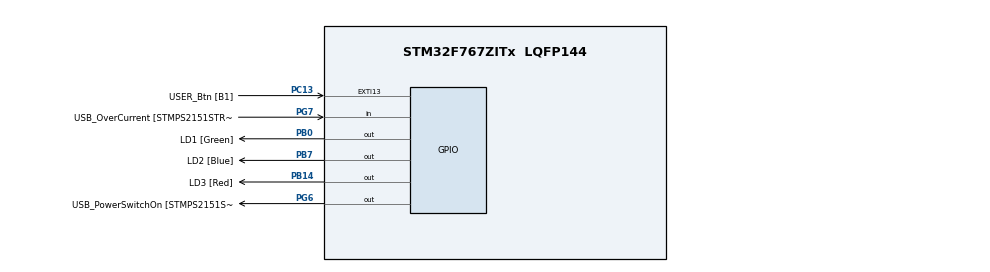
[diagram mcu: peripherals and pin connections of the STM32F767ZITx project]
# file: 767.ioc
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CORTEX_M7.CPU_DCache=Enabled
CORTEX_M7.CPU_ICache=Enabled
CORTEX_M7.FlashInterface=TCM_Enabled
Mcu.Family=STM32F7
Mcu.Name=STM32F767ZITx
Mcu.Package=LQFP144
NVIC.PriorityGroup=NVIC_PRIORITYGROUP_4
PA1.GPIO_Label=RMII_REF_CLK [LAN8742A-CZ-TR_REFCLK0]
PA1.Signal=ETH_REF_CLK
PA10.GPIO_Label=USB_ID
PA10.Signal=USB_OTG_FS_ID
PA11.GPIO_Label=USB_DM
PA11.Signal=USB_OTG_FS_DM
PA12.GPIO_Label=USB_DP
PA12.Signal=USB_OTG_FS_DP
PA13.GPIO_Label=TMS
PA13.Mode=Serial_Wire
PA13.Signal=SYS_JTMS-SWDIO
PA14.GPIO_Label=TCK
PA14.Mode=Serial_Wire
PA14.Signal=SYS_JTCK-SWCLK
PA2.GPIO_Label=RMII_MDIO [LAN8742A-CZ-TR_MDIO]
PA2.Signal=ETH_MDIO
PA7.GPIO_Label=RMII_CRS_DV [LAN8742A-CZ-TR_CRS_DV]
PA7.Signal=ETH_CRS_DV
PA8.GPIO_Label=USB_SOF [TP1]
PA8.Signal=USB_OTG_FS_SOF
PA9.GPIO_Label=USB_VBUS
PA9.Signal=USB_OTG_FS_VBUS
PB0.GPIO_Label=LD1 [Green]
PB0.Signal=GPIO_Output
PB13.GPIO_Label=RMII_TXD1 [LAN8742A-CZ-TR_TXD1]
PB13.Signal=ETH_TXD1
PB14.GPIO_Label=LD3 [Red]
PB14.Signal=GPIO_Output
PB3.GPIO_Label=SW0
PB3.Signal=SYS_JTDO-SWO
PB7.GPIO_Label=LD2 [Blue]
PB7.Signal=GPIO_Output
PC1.GPIO_Label=RMII_MDC [LAN8742A-CZ-TR_MDC]
PC1.Signal=ETH_MDC
PC13.GPIO_Label=USER_Btn [B1]
PC13.Signal=GPXTI13
PC14/OSC32_IN.Signal=RCC_OSC32_IN
PC15/OSC32_OUT.Signal=RCC_OSC32_OUT
PC4.GPIO_Label=RMII_RXD0 [LAN8742A-CZ-TR_RXD0]
PC4.Signal=ETH_RXD0
PC5.GPIO_Label=RMII_RXD1 [LAN8742A-CZ-TR_RXD1]
PC5.Signal=ETH_RXD1
PD8.GPIO_Label=STLK_RX [STM32F103CBT6_PA3]
PD8.Signal=USART3_TX
PD9.GPIO_Label=STLK_TX [STM32F103CBT6_PA2]
PD9.Signal=USART3_RX
PG11.GPIO_Label=RMII_TX_EN [LAN8742A-CZ-TR_TXEN]
PG11.Signal=ETH_TX_EN
PG13.GPIO_Label=RMII_TXD0 [LAN8742A-CZ-TR_TXD0]
PG13.Signal=ETH_TXD0
PG6.GPIO_Label=USB_PowerSwitchOn [STMPS2151STR_EN]
PG6.Signal=GPIO_Output
PG7.GPIO_Label=USB_OverCurrent [STMPS2151STR_FAULT]
PG7.Signal=GPIO_Input
PH0/OSC_IN.GPIO_Label=MCO [STM32F103CBT6_PA8]
PH0/OSC_IN.Mode=HSE-External-Clock-Source
PH0/OSC_IN.Signal=RCC_OSC_IN
PH1/OSC_OUT.Mode=HSE-External-Clock-Source
PH1/OSC_OUT.Signal=RCC_OSC_OUT
ProjectManager.HeapSize=0x200
ProjectManager.StackSize=0x400
ProjectManager.TargetToolchain=Makefile
RCC.48MHZClocksFreq_Value=24000000
RCC.AHBFreq_Value=216000000
RCC.APB1CLKDivider=RCC_HCLK_DIV4
RCC.APB1Freq_Value=54000000
RCC.APB1TimFreq_Value=108000000
RCC.APB2CLKDivider=RCC_HCLK_DIV2
RCC.APB2Freq_Value=108000000
RCC.APB2TimFreq_Value=216000000
RCC.CortexFreq_Value=216000000
RCC.EnbaleCSS=true
RCC.HCLKFreq_Value=216000000
RCC.HSE_VALUE=8000000
RCC.HSI_VALUE=16000000
RCC.LSE_VALUE=32768
RCC.PLLM=4
RCC.PLLMUL=RCC_PLL_MUL9
RCC.PLLN=216
RCC.PLLSourceVirtual=RCC_PLLSOURCE_HSE
RCC.PRESCALERUSB=RCC_USBCLKSOURCE_PLL_DIV1_5
RCC.SYSCLKFreq_VALUE=216000000
RCC.SYSCLKSource=RCC_SYSCLKSOURCE_PLLCLK
RCC.SYSCLKSourceVirtual=RCC_SYSCLKSOURCE_PLLCLK
RCC.USBFreq_Value=216000000
RCC.VCOOutputFreq_Value=432000000
board=NUCLEO-F767ZI

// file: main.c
//#include "main.h"
void SystemClock_Config(void);
static void MX_GPIO_Init(void);
int main(void)
{
  SCB_EnableICache();
  SCB_EnableDCache();//into (startup.S:64 bl) SystemInit
  /* Reset of all peripherals, Initializes the Flash interface and the Systick. */
  LL_APB1_GRP1_EnableClock(LL_APB1_GRP1_PERIPH_PWR);
  LL_APB2_GRP1_EnableClock(LL_APB2_GRP1_PERIPH_SYSCFG);
  /* System interrupt init*/
  NVIC_SetPriorityGrouping(NVIC_PRIORITYGROUP_4);
//  SystemClock_Config(); no, SystemInit should take care of
  MX_GPIO_Init();
  while (1)
  {
  }
}//main

void SystemClock_Config(void)
{
  LL_FLASH_SetLatency(LL_FLASH_LATENCY_7);
  while(LL_FLASH_GetLatency()!= LL_FLASH_LATENCY_7)
  {
  }
  LL_PWR_SetRegulVoltageScaling(LL_PWR_REGU_VOLTAGE_SCALE1);
  LL_PWR_EnableOverDriveMode();
  LL_RCC_HSE_EnableBypass();
  LL_RCC_HSE_Enable();
   /* Wait till HSE is ready */
  while(LL_RCC_HSE_IsReady() != 1)
  {
  }
  LL_RCC_HSE_EnableCSS();
  LL_RCC_PLL_ConfigDomain_SYS(LL_RCC_PLLSOURCE_HSE, LL_RCC_PLLM_DIV_4, 216, LL_RCC_PLLP_DIV_2);
  LL_RCC_PLL_Enable();
   /* Wait till PLL is ready */
  while(LL_RCC_PLL_IsReady() != 1)
  {
  }
  while (LL_PWR_IsActiveFlag_VOS() == 0)
  {
  }
  LL_RCC_SetAHBPrescaler(LL_RCC_SYSCLK_DIV_1);
  LL_RCC_SetAPB1Prescaler(LL_RCC_APB1_DIV_4);
  LL_RCC_SetAPB2Prescaler(LL_RCC_APB2_DIV_2);
  LL_RCC_SetSysClkSource(LL_RCC_SYS_CLKSOURCE_PLL);
   /* Wait till System clock is ready */
  while(LL_RCC_GetSysClkSource() != LL_RCC_SYS_CLKSOURCE_STATUS_PLL)
  {
  }
  LL_Init1msTick(216000000);
  LL_SetSystemCoreClock(216000000);
   /* Set Timers Clock Prescalers */
  LL_RCC_SetTIMPrescaler(LL_RCC_TIM_PRESCALER_TWICE);
}

static void MX_GPIO_Init(void)
{
  LL_EXTI_InitTypeDef EXTI_InitStruct = {0};
  LL_GPIO_InitTypeDef GPIO_InitStruct = {0};
  /* GPIO Ports Clock Enable */
  LL_AHB1_GRP1_EnableClock(LL_AHB1_GRP1_PERIPH_GPIOC);
  LL_AHB1_GRP1_EnableClock(LL_AHB1_GRP1_PERIPH_GPIOH);
  LL_AHB1_GRP1_EnableClock(LL_AHB1_GRP1_PERIPH_GPIOA);
  LL_AHB1_GRP1_EnableClock(LL_AHB1_GRP1_PERIPH_GPIOB);
  LL_AHB1_GRP1_EnableClock(LL_AHB1_GRP1_PERIPH_GPIOD);
  LL_AHB1_GRP1_EnableClock(LL_AHB1_GRP1_PERIPH_GPIOG);

  /**/
  LL_GPIO_ResetOutputPin(LD1_GPIO_Port, LD1_Pin);

  /**/
  LL_GPIO_ResetOutputPin(LD3_GPIO_Port, LD3_Pin);

  /**/
  LL_GPIO_ResetOutputPin(USB_PowerSwitchOn_GPIO_Port, USB_PowerSwitchOn_Pin);

  /**/
  LL_GPIO_ResetOutputPin(LD2_GPIO_Port, LD2_Pin);

  /**/
  LL_SYSCFG_SetEXTISource(LL_SYSCFG_EXTI_PORTC, LL_SYSCFG_EXTI_LINE13);

  /**/
  EXTI_InitStruct.Line_0_31 = LL_EXTI_LINE_13;
  EXTI_InitStruct.LineCommand = ENABLE;
  EXTI_InitStruct.Mode = LL_EXTI_MODE_IT;
  EXTI_InitStruct.Trigger = LL_EXTI_TRIGGER_RISING;
  LL_EXTI_Init(&EXTI_InitStruct);

  /**/
  LL_GPIO_SetPinPull(USER_Btn_GPIO_Port, USER_Btn_Pin, LL_GPIO_PULL_NO);

  /**/
  LL_GPIO_SetPinMode(USER_Btn_GPIO_Port, USER_Btn_Pin, LL_GPIO_MODE_INPUT);

  /**/
  GPIO_InitStruct.Pin = RMII_MDC_Pin;
  GPIO_InitStruct.Mode = LL_GPIO_MODE_ALTERNATE;
  GPIO_InitStruct.Speed = LL_GPIO_SPEED_FREQ_VERY_HIGH;
  GPIO_InitStruct.OutputType = LL_GPIO_OUTPUT_PUSHPULL;
  GPIO_InitStruct.Pull = LL_GPIO_PULL_NO;
  GPIO_InitStruct.Alternate = LL_GPIO_AF_11;
  LL_GPIO_Init(RMII_MDC_GPIO_Port, &GPIO_InitStruct);

  /**/
  GPIO_InitStruct.Pin = RMII_REF_CLK_Pin;
  GPIO_InitStruct.Mode = LL_GPIO_MODE_ALTERNATE;
  GPIO_InitStruct.Speed = LL_GPIO_SPEED_FREQ_VERY_HIGH;
  GPIO_InitStruct.OutputType = LL_GPIO_OUTPUT_PUSHPULL;
  GPIO_InitStruct.Pull = LL_GPIO_PULL_NO;
  GPIO_InitStruct.Alternate = LL_GPIO_AF_11;
  LL_GPIO_Init(RMII_REF_CLK_GPIO_Port, &GPIO_InitStruct);

  /**/
  GPIO_InitStruct.Pin = RMII_MDIO_Pin;
  GPIO_InitStruct.Mode = LL_GPIO_MODE_ALTERNATE;
  GPIO_InitStruct.Speed = LL_GPIO_SPEED_FREQ_VERY_HIGH;
  GPIO_InitStruct.OutputType = LL_GPIO_OUTPUT_PUSHPULL;
  GPIO_InitStruct.Pull = LL_GPIO_PULL_NO;
  GPIO_InitStruct.Alternate = LL_GPIO_AF_11;
  LL_GPIO_Init(RMII_MDIO_GPIO_Port, &GPIO_InitStruct);

  /**/
  GPIO_InitStruct.Pin = RMII_CRS_DV_Pin;
  GPIO_InitStruct.Mode = LL_GPIO_MODE_ALTERNATE;
  GPIO_InitStruct.Speed = LL_GPIO_SPEED_FREQ_VERY_HIGH;
  GPIO_InitStruct.OutputType = LL_GPIO_OUTPUT_PUSHPULL;
  GPIO_InitStruct.Pull = LL_GPIO_PULL_NO;
  GPIO_InitStruct.Alternate = LL_GPIO_AF_11;
  LL_GPIO_Init(RMII_CRS_DV_GPIO_Port, &GPIO_InitStruct);

  /**/
  GPIO_InitStruct.Pin = RMII_RXD0_Pin;
  GPIO_InitStruct.Mode = LL_GPIO_MODE_ALTERNATE;
  GPIO_InitStruct.Speed = LL_GPIO_SPEED_FREQ_VERY_HIGH;
  GPIO_InitStruct.OutputType = LL_GPIO_OUTPUT_PUSHPULL;
  GPIO_InitStruct.Pull = LL_GPIO_PULL_NO;
  GPIO_InitStruct.Alternate = LL_GPIO_AF_11;
  LL_GPIO_Init(RMII_RXD0_GPIO_Port, &GPIO_InitStruct);

  /**/
  GPIO_InitStruct.Pin = RMII_RXD1_Pin;
  GPIO_InitStruct.Mode = LL_GPIO_MODE_ALTERNATE;
  GPIO_InitStruct.Speed = LL_GPIO_SPEED_FREQ_VERY_HIGH;
  GPIO_InitStruct.OutputType = LL_GPIO_OUTPUT_PUSHPULL;
  GPIO_InitStruct.Pull = LL_GPIO_PULL_NO;
  GPIO_InitStruct.Alternate = LL_GPIO_AF_11;
  LL_GPIO_Init(RMII_RXD1_GPIO_Port, &GPIO_InitStruct);

  /**/
  GPIO_InitStruct.Pin = LD1_Pin;
  GPIO_InitStruct.Mode = LL_GPIO_MODE_OUTPUT;
  GPIO_InitStruct.Speed = LL_GPIO_SPEED_FREQ_LOW;
  GPIO_InitStruct.OutputType = LL_GPIO_OUTPUT_PUSHPULL;
  GPIO_InitStruct.Pull = LL_GPIO_PULL_NO;
  LL_GPIO_Init(LD1_GPIO_Port, &GPIO_InitStruct);

  /**/
  GPIO_InitStruct.Pin = RMII_TXD1_Pin;
  GPIO_InitStruct.Mode = LL_GPIO_MODE_ALTERNATE;
  GPIO_InitStruct.Speed = LL_GPIO_SPEED_FREQ_VERY_HIGH;
  GPIO_InitStruct.OutputType = LL_GPIO_OUTPUT_PUSHPULL;
  GPIO_InitStruct.Pull = LL_GPIO_PULL_NO;
  GPIO_InitStruct.Alternate = LL_GPIO_AF_11;
  LL_GPIO_Init(RMII_TXD1_GPIO_Port, &GPIO_InitStruct);

  /**/
  GPIO_InitStruct.Pin = LD3_Pin;
  GPIO_InitStruct.Mode = LL_GPIO_MODE_OUTPUT;
  GPIO_InitStruct.Speed = LL_GPIO_SPEED_FREQ_LOW;
  GPIO_InitStruct.OutputType = LL_GPIO_OUTPUT_PUSHPULL;
  GPIO_InitStruct.Pull = LL_GPIO_PULL_NO;
  LL_GPIO_Init(LD3_GPIO_Port, &GPIO_InitStruct);

  /**/
  GPIO_InitStruct.Pin = STLK_RX_Pin;
  GPIO_InitStruct.Mode = LL_GPIO_MODE_ALTERNATE;
  GPIO_InitStruct.Speed = LL_GPIO_SPEED_FREQ_VERY_HIGH;
  GPIO_InitStruct.OutputType = LL_GPIO_OUTPUT_PUSHPULL;
  GPIO_InitStruct.Pull = LL_GPIO_PULL_NO;
  GPIO_InitStruct.Alternate = LL_GPIO_AF_7;
  LL_GPIO_Init(STLK_RX_GPIO_Port, &GPIO_InitStruct);

  /**/
  GPIO_InitStruct.Pin = STLK_TX_Pin;
  GPIO_InitStruct.Mode = LL_GPIO_MODE_ALTERNATE;
  GPIO_InitStruct.Speed = LL_GPIO_SPEED_FREQ_VERY_HIGH;
  GPIO_InitStruct.OutputType = LL_GPIO_OUTPUT_PUSHPULL;
  GPIO_InitStruct.Pull = LL_GPIO_PULL_NO;
  GPIO_InitStruct.Alternate = LL_GPIO_AF_7;
  LL_GPIO_Init(STLK_TX_GPIO_Port, &GPIO_InitStruct);

  /**/
  GPIO_InitStruct.Pin = USB_PowerSwitchOn_Pin;
  GPIO_InitStruct.Mode = LL_GPIO_MODE_OUTPUT;
  GPIO_InitStruct.Speed = LL_GPIO_SPEED_FREQ_LOW;
  GPIO_InitStruct.OutputType = LL_GPIO_OUTPUT_PUSHPULL;
  GPIO_InitStruct.Pull = LL_GPIO_PULL_NO;
  LL_GPIO_Init(USB_PowerSwitchOn_GPIO_Port, &GPIO_InitStruct);

  /**/
  GPIO_InitStruct.Pin = USB_OverCurrent_Pin;
  GPIO_InitStruct.Mode = LL_GPIO_MODE_INPUT;
  GPIO_InitStruct.Pull = LL_GPIO_PULL_NO;
  LL_GPIO_Init(USB_OverCurrent_GPIO_Port, &GPIO_InitStruct);

  /**/
  GPIO_InitStruct.Pin = USB_SOF_Pin;
  GPIO_InitStruct.Mode = LL_GPIO_MODE_ALTERNATE;
  GPIO_InitStruct.Speed = LL_GPIO_SPEED_FREQ_VERY_HIGH;
  GPIO_InitStruct.OutputType = LL_GPIO_OUTPUT_PUSHPULL;
  GPIO_InitStruct.Pull = LL_GPIO_PULL_NO;
  GPIO_InitStruct.Alternate = LL_GPIO_AF_10;
  LL_GPIO_Init(USB_SOF_GPIO_Port, &GPIO_InitStruct);

  /**/
  GPIO_InitStruct.Pin = USB_VBUS_Pin;
  GPIO_InitStruct.Mode = LL_GPIO_MODE_INPUT;
  GPIO_InitStruct.Pull = LL_GPIO_PULL_NO;
  LL_GPIO_Init(USB_VBUS_GPIO_Port, &GPIO_InitStruct);

  /**/
  GPIO_InitStruct.Pin = USB_ID_Pin;
  GPIO_InitStruct.Mode = LL_GPIO_MODE_ALTERNATE;
  GPIO_InitStruct.Speed = LL_GPIO_SPEED_FREQ_VERY_HIGH;
  GPIO_InitStruct.OutputType = LL_GPIO_OUTPUT_PUSHPULL;
  GPIO_InitStruct.Pull = LL_GPIO_PULL_NO;
  GPIO_InitStruct.Alternate = LL_GPIO_AF_10;
  LL_GPIO_Init(USB_ID_GPIO_Port, &GPIO_InitStruct);

  /**/
  GPIO_InitStruct.Pin = USB_DM_Pin;
  GPIO_InitStruct.Mode = LL_GPIO_MODE_ALTERNATE;
  GPIO_InitStruct.Speed = LL_GPIO_SPEED_FREQ_VERY_HIGH;
  GPIO_InitStruct.OutputType = LL_GPIO_OUTPUT_PUSHPULL;
  GPIO_InitStruct.Pull = LL_GPIO_PULL_NO;
  GPIO_InitStruct.Alternate = LL_GPIO_AF_10;
  LL_GPIO_Init(USB_DM_GPIO_Port, &GPIO_InitStruct);

  /**/
  GPIO_InitStruct.Pin = USB_DP_Pin;
  GPIO_InitStruct.Mode = LL_GPIO_MODE_ALTERNATE;
  GPIO_InitStruct.Speed = LL_GPIO_SPEED_FREQ_VERY_HIGH;
  GPIO_InitStruct.OutputType = LL_GPIO_OUTPUT_PUSHPULL;
  GPIO_InitStruct.Pull = LL_GPIO_PULL_NO;
  GPIO_InitStruct.Alternate = LL_GPIO_AF_10;
  LL_GPIO_Init(USB_DP_GPIO_Port, &GPIO_InitStruct);

  /**/
  GPIO_InitStruct.Pin = RMII_TX_EN_Pin;
  GPIO_InitStruct.Mode = LL_GPIO_MODE_ALTERNATE;
  GPIO_InitStruct.Speed = LL_GPIO_SPEED_FREQ_VERY_HIGH;
  GPIO_InitStruct.OutputType = LL_GPIO_OUTPUT_PUSHPULL;
  GPIO_InitStruct.Pull = LL_GPIO_PULL_NO;
  GPIO_InitStruct.Alternate = LL_GPIO_AF_11;
  LL_GPIO_Init(RMII_TX_EN_GPIO_Port, &GPIO_InitStruct);

  /**/
  GPIO_InitStruct.Pin = RMII_TXD0_Pin;
  GPIO_InitStruct.Mode = LL_GPIO_MODE_ALTERNATE;
  GPIO_InitStruct.Speed = LL_GPIO_SPEED_FREQ_VERY_HIGH;
  GPIO_InitStruct.OutputType = LL_GPIO_OUTPUT_PUSHPULL;
  GPIO_InitStruct.Pull = LL_GPIO_PULL_NO;
  GPIO_InitStruct.Alternate = LL_GPIO_AF_11;
  LL_GPIO_Init(RMII_TXD0_GPIO_Port, &GPIO_InitStruct);

  /**/
  GPIO_InitStruct.Pin = LD2_Pin;
  GPIO_InitStruct.Mode = LL_GPIO_MODE_OUTPUT;
  GPIO_InitStruct.Speed = LL_GPIO_SPEED_FREQ_LOW;
  GPIO_InitStruct.OutputType = LL_GPIO_OUTPUT_PUSHPULL;
  GPIO_InitStruct.Pull = LL_GPIO_PULL_NO;
  LL_GPIO_Init(LD2_GPIO_Port, &GPIO_InitStruct);

}
void Error_Handler(void)
{
  __disable_irq();
  while (1)
  {
  }
}

#ifdef  USE_FULL_ASSERT
/**
  * @brief  Reports the name of the source file and the source line number
  *         where the assert_param error has occurred.
  * @param  file: pointer to the source file name
  * @param  line: assert_param error line source number
  * @retval None
  */
void assert_failed(uint8_t *file, uint32_t line)
{
  /* USER CODE BEGIN 6 */
  /* User can add his own implementation to report the file name and line number,
// vim complains about this 'ex:'     \e\x\: printf("Wrong parameters value: file %s on line %d\r\n", file, line) */
  /* USER CODE END 6 */
}
#endif /* USE_FULL_ASSERT */
